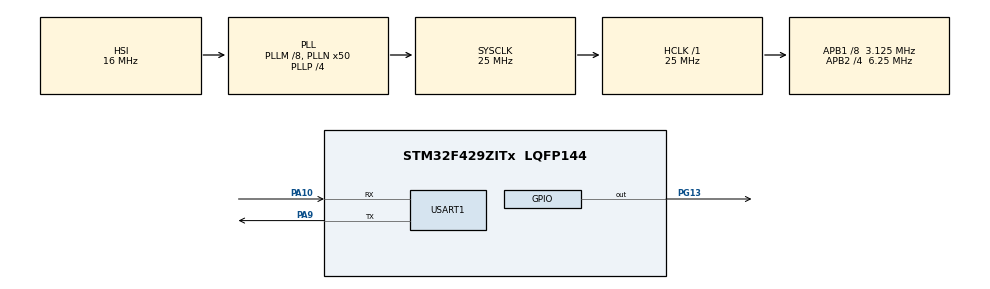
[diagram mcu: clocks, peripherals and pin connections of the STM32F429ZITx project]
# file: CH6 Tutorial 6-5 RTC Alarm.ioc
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Mcu.Family=STM32F4
Mcu.Name=STM32F429ZITx
Mcu.Package=LQFP144
NVIC.PriorityGroup=NVIC_PRIORITYGROUP_0
NVIC.RTC_Alarm_IRQn=true\:0\:0\:false\:false\:true\:true\:true\:true
PA10.Mode=Asynchronous
PA10.Signal=USART1_RX
PA9.Mode=Asynchronous
PA9.Signal=USART1_TX
PG13.Signal=GPIO_Output
PH0/OSC_IN.Mode=HSE-External-Oscillator
PH0/OSC_IN.Signal=RCC_OSC_IN
PH1/OSC_OUT.Mode=HSE-External-Oscillator
PH1/OSC_OUT.Signal=RCC_OSC_OUT
ProjectManager.HeapSize=0x200
ProjectManager.StackSize=0x400
ProjectManager.TargetToolchain=STM32CubeIDE
RCC.48MHZClocksFreq_Value=14285714.285714285
RCC.AHBFreq_Value=25000000
RCC.APB1CLKDivider=RCC_HCLK_DIV8
RCC.APB1Freq_Value=3125000
RCC.APB1TimFreq_Value=6250000
RCC.APB2CLKDivider=RCC_HCLK_DIV4
RCC.APB2Freq_Value=6250000
RCC.APB2TimFreq_Value=12500000
RCC.CortexFreq_Value=25000000
RCC.HCLKFreq_Value=25000000
RCC.HSE_VALUE=8000000
RCC.HSI_VALUE=16000000
RCC.LSE_VALUE=32768
RCC.PLLM=8
RCC.PLLN=50
RCC.PLLP=RCC_PLLP_DIV4
RCC.PLLQ=7
RCC.RCC_RTC_Clock_SourceVirtual=RCC_RTCCLKSOURCE_HSE_DIV25
RCC.RCC_RTC_Clock_Source_FROM_HSE=RCC_RTCCLKSOURCE_HSE_DIV25
RCC.SYSCLKFreq_VALUE=25000000
RCC.SYSCLKSource=RCC_SYSCLKSOURCE_PLLCLK
RCC.VCOOutputFreq_Value=100000000
RTC.Alarm=RTC_ALARM_A
RTC.AlarmDateWeekDay=RTC_WEEKDAY_THURSDAY
RTC.AlarmDateWeekDaySel=RTC_ALARMDATEWEEKDAYSEL_WEEKDAY
RTC.AsynchPrediv=125-1
RTC.Date=2
RTC.DayLightSaving=RTC_DAYLIGHTSAVING_SUB1H
RTC.Hours=14
RTC.Hours_A=14
RTC.Minutes=0
RTC.Minutes_A=0
RTC.Month=RTC_MONTH_NOVEMBER
RTC.Seconds_A=30
RTC.SynchPrediv=2560-1
RTC.WeekDay=RTC_WEEKDAY_THURSDAY
RTC.Year=23
USART1.OverSampling=UART_OVERSAMPLING_8
USART1.VirtualMode=VM_ASYNC
VP_RTC_VS_RTC_Activate.Mode=RTC_Enabled
VP_RTC_VS_RTC_Alarm_A_Intern.Mode=Alarm A
VP_RTC_VS_RTC_Calendar.Mode=RTC_Calendar
board=STM32F429I-DISC1

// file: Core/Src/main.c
/* USER CODE BEGIN Header */
/**
  ******************************************************************************
  * @file           : main.c
  * @brief          : Main program body
  ******************************************************************************
  * @attention
  *
  * Copyright (c) 2023 STMicroelectronics.
  * All rights reserved.
  *
  * This software is licensed under terms that can be found in the LICENSE file
  * in the root directory of this software component.
  * If no LICENSE file comes with this software, it is provided AS-IS.
  *
  ******************************************************************************
  */

	/***************************** Tutorial Tags ******************************
	 Real Time Clock (RTC) Timer
	 Alarm Interrupt
	 GPIO Digital output
     UART - printf() on Cube console
	 **************************************************************************/

	/* 6.4.1 Timer Usage C Language: ******************************************
	* Tutorial 6-5: Using the alarm property of RTC, in C language
	*

    In this tutorial, use the RTC clock module to setting the RTC alarm and toggle
    a led following the alarm set off in 30 seconds. For this, set the RTC clock
    and the alarm, enable the alarm to generate an interrupt which is used to toggle
    the green led connected to PG13.

    The tutorial is extended to use printf() to print the time and date when the led
    is toggled.
    Note: Try to avoid executing the printf within the callback function since it is slow

    For tutorial on using printf() refer to "_Nucleo-printf "
	***************************************************************************/
/* USER CODE END Header */
#include "main.h"

/* USER CODE BEGIN Includes */
#include <stdio.h>
/* USER CODE END Includes */

RTC_HandleTypeDef hrtc;

UART_HandleTypeDef huart1;

RTC_DateTypeDef gDate;
RTC_TimeTypeDef gTime;

/* USER CODE BEGIN PV */
uint32_t Flag = 0;
char date [80], time [80];
/* USER CODE END PV */

void SystemClock_Config(void);
static void MX_GPIO_Init(void);
static void MX_RTC_Init(void);
static void MX_USART1_UART_Init(void);

/* USER CODE BEGIN 0 */
int _write(int file, char *ptr, int len){
	HAL_UART_Transmit(&huart1, (uint8_t*)ptr, len, HAL_MAX_DELAY);
	return len;
}
/* USER CODE END 0 */

int main(void)
{

  /* MCU Configuration--------------------------------------------------------*/

  /* Reset of all peripherals, Initializes the Flash interface and the Systick. */
  HAL_Init();

  /* Configure the system clock */
  SystemClock_Config();

  /* Initialize all configured peripherals */
  MX_GPIO_Init();
  MX_RTC_Init();
  MX_USART1_UART_Init();

  /* Infinite loop */
  /* USER CODE BEGIN WHILE */
  while (1)
  {
	  if(Flag ==1){
		  printf("DATE AND TIME IS:\r\n");
		  // Get date time when the alarm goes off
		  /* Get the RTC current Time */
		  HAL_RTC_GetTime(&hrtc, &gTime, RTC_FORMAT_BIN);
		  /* Get the RTC current Date */
		  HAL_RTC_GetDate(&hrtc, &gDate, RTC_FORMAT_BIN);
		  /* Display time Format: hh:mm:ss */
		  printf("%02d:%02d:%02d\r\n",gTime.Hours, gTime.Minutes, gTime.Seconds);
		  /* Display date Format: dd-mm-yy */
		  printf("%02d-%02d-%2d\r\n",gDate.Date, gDate.Month, 2000 + gDate.Year);
		  Flag = 0;
	  }
	  /* USER CODE END WHILE */

  }
}

void SystemClock_Config(void)
{
  RCC_OscInitTypeDef RCC_OscInitStruct = {0};
  RCC_ClkInitTypeDef RCC_ClkInitStruct = {0};

  /** Configure the main internal regulator output voltage
  */
  __HAL_RCC_PWR_CLK_ENABLE();
  __HAL_PWR_VOLTAGESCALING_CONFIG(PWR_REGULATOR_VOLTAGE_SCALE3);

  /** Initializes the RCC Oscillators according to the specified parameters
  * in the RCC_OscInitTypeDef structure.
  */
  RCC_OscInitStruct.OscillatorType = RCC_OSCILLATORTYPE_HSI|RCC_OSCILLATORTYPE_HSE;
  RCC_OscInitStruct.HSEState = RCC_HSE_ON;
  RCC_OscInitStruct.HSIState = RCC_HSI_ON;
  RCC_OscInitStruct.HSICalibrationValue = RCC_HSICALIBRATION_DEFAULT;
  RCC_OscInitStruct.PLL.PLLState = RCC_PLL_ON;
  RCC_OscInitStruct.PLL.PLLSource = RCC_PLLSOURCE_HSI;
  RCC_OscInitStruct.PLL.PLLM = 8;
  RCC_OscInitStruct.PLL.PLLN = 50;
  RCC_OscInitStruct.PLL.PLLP = RCC_PLLP_DIV4;
  RCC_OscInitStruct.PLL.PLLQ = 7;
  if (HAL_RCC_OscConfig(&RCC_OscInitStruct) != HAL_OK)
  {
    Error_Handler();
  }

  /** Initializes the CPU, AHB and APB buses clocks
  */
  RCC_ClkInitStruct.ClockType = RCC_CLOCKTYPE_HCLK|RCC_CLOCKTYPE_SYSCLK
                              |RCC_CLOCKTYPE_PCLK1|RCC_CLOCKTYPE_PCLK2;
  RCC_ClkInitStruct.SYSCLKSource = RCC_SYSCLKSOURCE_PLLCLK;
  RCC_ClkInitStruct.AHBCLKDivider = RCC_SYSCLK_DIV1;
  RCC_ClkInitStruct.APB1CLKDivider = RCC_HCLK_DIV8;
  RCC_ClkInitStruct.APB2CLKDivider = RCC_HCLK_DIV4;

  if (HAL_RCC_ClockConfig(&RCC_ClkInitStruct, FLASH_LATENCY_0) != HAL_OK)
  {
    Error_Handler();
  }
}

static void MX_RTC_Init(void)
{

  RTC_TimeTypeDef sTime = {0};
  RTC_DateTypeDef sDate = {0};
  RTC_AlarmTypeDef sAlarm = {0};

  /** Initialize RTC Only
  */
  hrtc.Instance = RTC;
  hrtc.Init.HourFormat = RTC_HOURFORMAT_24;
  hrtc.Init.AsynchPrediv = 125-1;
  hrtc.Init.SynchPrediv = 2560-1;
  hrtc.Init.OutPut = RTC_OUTPUT_DISABLE;
  hrtc.Init.OutPutPolarity = RTC_OUTPUT_POLARITY_HIGH;
  hrtc.Init.OutPutType = RTC_OUTPUT_TYPE_OPENDRAIN;
  if (HAL_RTC_Init(&hrtc) != HAL_OK)
  {
    Error_Handler();
  }

  /** Initialize RTC and set the Time and Date
  */
  sTime.Hours = 0x12;
  sTime.Minutes = 0x0;
  sTime.Seconds = 0x0;
  sTime.DayLightSaving = RTC_DAYLIGHTSAVING_SUB1H;
  sTime.StoreOperation = RTC_STOREOPERATION_RESET;
  if (HAL_RTC_SetTime(&hrtc, &sTime, RTC_FORMAT_BCD) != HAL_OK)
  {
    Error_Handler();
  }
  sDate.WeekDay = RTC_WEEKDAY_SUNDAY;
  sDate.Month = RTC_MONTH_JANUARY;
  sDate.Date = 0x1;
  sDate.Year = 0x23;

  if (HAL_RTC_SetDate(&hrtc, &sDate, RTC_FORMAT_BCD) != HAL_OK)
  {
    Error_Handler();
  }

  /** Enable the Alarm A
  */
  sAlarm.AlarmTime.Hours = 0x12;
  sAlarm.AlarmTime.Minutes = 0x0;
  sAlarm.AlarmTime.Seconds = 0x30;
  sAlarm.AlarmTime.SubSeconds = 0x0;
  sAlarm.AlarmTime.DayLightSaving = RTC_DAYLIGHTSAVING_SUB1H;
  sAlarm.AlarmTime.StoreOperation = RTC_STOREOPERATION_RESET;
  sAlarm.AlarmMask = RTC_ALARMMASK_NONE;
  sAlarm.AlarmSubSecondMask = RTC_ALARMSUBSECONDMASK_ALL;
  sAlarm.AlarmDateWeekDaySel = RTC_ALARMDATEWEEKDAYSEL_WEEKDAY;
  sAlarm.AlarmDateWeekDay = RTC_WEEKDAY_SUNDAY;
  sAlarm.Alarm = RTC_ALARM_A;
  if (HAL_RTC_SetAlarm_IT(&hrtc, &sAlarm, RTC_FORMAT_BCD) != HAL_OK)
  {
    Error_Handler();
  }

}

static void MX_USART1_UART_Init(void)
{

  huart1.Instance = USART1;
  huart1.Init.BaudRate = 115200;
  huart1.Init.WordLength = UART_WORDLENGTH_8B;
  huart1.Init.StopBits = UART_STOPBITS_1;
  huart1.Init.Parity = UART_PARITY_NONE;
  huart1.Init.Mode = UART_MODE_TX_RX;
  huart1.Init.HwFlowCtl = UART_HWCONTROL_NONE;
  huart1.Init.OverSampling = UART_OVERSAMPLING_8;
  if (HAL_UART_Init(&huart1) != HAL_OK)
  {
    Error_Handler();
  }

}

static void MX_GPIO_Init(void)
{
  GPIO_InitTypeDef GPIO_InitStruct = {0};

  /* GPIO Ports Clock Enable */
  __HAL_RCC_GPIOH_CLK_ENABLE();
  __HAL_RCC_GPIOA_CLK_ENABLE();
  __HAL_RCC_GPIOG_CLK_ENABLE();

  /*Configure GPIO pin Output Level */
  HAL_GPIO_WritePin(GPIOG, GPIO_PIN_13, GPIO_PIN_RESET);

  /*Configure GPIO pin : PG13 */
  GPIO_InitStruct.Pin = GPIO_PIN_13;
  GPIO_InitStruct.Mode = GPIO_MODE_OUTPUT_PP;
  GPIO_InitStruct.Pull = GPIO_NOPULL;
  GPIO_InitStruct.Speed = GPIO_SPEED_FREQ_LOW;
  HAL_GPIO_Init(GPIOG, &GPIO_InitStruct);

}

/* USER CODE BEGIN 4 */
void HAL_RTC_AlarmAEventCallback(RTC_HandleTypeDef *hrtc)
{
	// Toggle GP13 led when the alarm goes off
	HAL_GPIO_TogglePin(GPIOG, GPIO_PIN_13);
	// Set a flag to 1 for uusing printf () in CPU loop
	Flag = 1;
}

/* USER CODE END 4 */

void Error_Handler(void)
{
  __disable_irq();
  while (1)
  {
  }
}
